# PIC32CM6408PL10028 device description
Architecture: CORTEX-M0PLUS; Family: PIC32CMPL; Series: PIC32CMPL10
Registers are 32-bit, read-write, reset 0x0 unless marked. A register's access mark holds for its fields unless they carry their own. Offsets are from the block's base; [hi:lo] are bit positions; {n}, {i} and the like mark numbered series; 'fields as' and 'values as' point back to an identical list.

## FUSES_BOOTCFG — Non-Volatile Fuses
Instances: FUSES_BOOTCFG 0x0D000400
0x00 SEQNUM reset 0xFFFFFFFF — Sequence Number Fuse
  [31:0] SEQNUM — Sequence Number
0x08 BOOTPROT reset 0xFFFFFFFF — Boot Protection Fuse
  [2:0] BOOTPROT — Boot Protection
    0=SIZE_32768BYTES (32768 bytes are protected.); 1=SIZE_16384BYTES (16384 bytes are protected.); 2=SIZE_8192BYTES (8192 bytes are protected.); 3=SIZE_4096BYTES (4096 bytes are protected.); 4=SIZE_2048BYTES (2048 bytes are protected.); 5=SIZE_1024BYTES (1024 bytes are protected.); 6=SIZE_512BYTES (512 bytes are protected.); 7=SIZE_0BYTES (0 bytes are protected.)
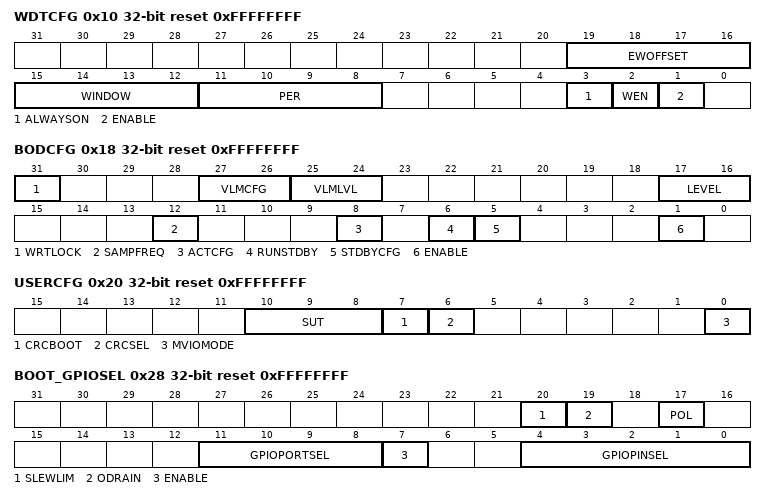
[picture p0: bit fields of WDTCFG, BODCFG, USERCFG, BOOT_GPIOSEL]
0x10 WDTCFG reset 0xFFFFFFFF — Watchdog Timer Configuration Fuse
  [19:16] EWOFFSET — Early Warning Interrupt Time Offset Fuse
    0=CYC8 (8 clock cycles); 1=CYC16 (16 clock cycles); 2=CYC32 (32 clock cycles); 3=CYC64 (64 clock cycles); 4=CYC128 (128 clock cycles); 5=CYC256 (256 clock cycles); 6=CYC512 (512 clock cycles); 7=CYC1024 (1024 clock cycles); 8=CYC2048 (2048 clock cycles); 9=CYC4096 (4096 clock cycles); 10=CYC8192 (8192 clock cycles); 11=CYC16384 (16384 clock cycles)
  [15:12] WINDOW
    values as EWOFFSET
  [11:8] PER — Time-Out Period
    values as EWOFFSET
  [3] ALWAYSON
  [2] WEN — Window Mode Enable
  [1] ENABLE
0x18 BODCFG reset 0xFFFFFFFF — BOD Configuration Fuse
  [31] WRTLOCK — Write Lock
  [27:26] VLMCFG — Voltage Level Monitor Interrupt Configuration
    0=FALLING (VDD falls below VLM threshold); 1=RISING (VDD rises above VLM threshold); 2=BOTH (VDD crosses VLM threshold)
  [25:24] VLMLVL — Voltage Level Monitor Level
    0=OFF (VLM disabled); 1=5ABOVE (VLM threshold is 5% above BOD threshold)
  [17:16] LEVEL — BOD Level
    0=BODLEVEL0 (1.90V); 1=BODLEVEL1 (2.45V); 2=BODLEVEL2 (2.70V); 3=BODLEVEL3 (2.85V)
  [12] SAMPFREQ — BOD Sampling Frequency
    0=128HZ (128 Hz Sampling Frequency); 1=32HZ (32 Hz Sampling Frequency)
  [8] ACTCFG — BOD Operation Mode in Active Mode
    0=CONT (Continuous Mode); 1=SAMP (Sampling Mode)
  [6] RUNSTDBY — Run in Standby
  [5] STDBYCFG — BOD Configuration in Standby Sleep Mode
  [1] ENABLE — BOD Enable
0x20 USERCFG reset 0xFFFFFFFF — User Configuration Fuse
  [10:8] SUT — Start-up Time
    0=0MS; 1=1MS; 2=2MS; 3=4MS; 4=8MS; 5=16MS; 6=32MS; 7=64MS
  [7] CRCBOOT
  [6] CRCSEL — CRC Polynomial Selection
    0=CRC16 (CRC-16-CCITT); 1=CRC32 (CRC-32 (IEEE 802.3))
  [0] MVIOMODE — MVIO Operation Mode
    0=DUAL (MVIO operating in dual supply mode); 1=SINGLE (MVIO operating in Single supply mode)
0x28 BOOT_GPIOSEL reset 0xFFFFFFFF — Boot External Notification I/O Pin Fuse
  [20] SLEWLIM — Slew Rate Control for Boot External Notification Signal
    0=FALSE (The slew rate is not limited (fast rise/fall time operation)); 1=TRUE (The slew rate is limited.)
  [19] ODRAIN — Open Drain Control for Boot External Notification Signal
    0=FALSE (The selected fault source is open drain drive); 1=TRUE (The selected fault source is normal drive)
  [17] POL — Select Polarity in Normal Drive Mode for Boot External Notification Signal
    0=FALSE (The selected fault source is active-high); 1=TRUE (The selected fault source is active-low)
  [11:8] GPIOPORTSEL — GPIO Port Select for Boot External Notification Signal
    0=PORTA; 1=PORTB; 2=PORTC; 3=PORTD
  [7] ENABLE — Enable Boot External Notification Signal
  [4:0] GPIOPINSEL — GPIO Pin Select for Boot External Notification Signal
    0=PIN00; 1=PIN01 (Pin 1); 30=PIN30; 31=PIN31

## FUSES_SIGNATURE — Non-Volatile Fuses
Instances: FUSES_SIGNATURE 0x0D000200
{0x20+8i} SERNUM{i} ro reset 0xFFFFFFFF (i=0..3) — Serial Number {i}

## GCLK — Generic Clock Controller
Instances: GCLK 0x40001C00
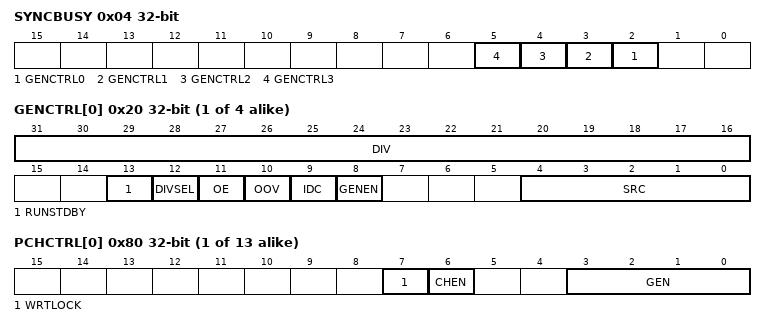
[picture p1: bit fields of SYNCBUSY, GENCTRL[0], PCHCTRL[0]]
0x04 SYNCBUSY ro — Synchronization Busy
  [n+2] GENCTRL{n} (n=0..3) — Generator Control {n} Synchronization Busy
{0x20+4i} GENCTRL[{i}] (i=0..3) (WSYNC) — Generator Control
  [31:16] DIV — Division Factor
  [13] RUNSTDBY — Run in Standby
  [12] DIVSEL — Divide Selection
    0=DIV1 (The Generator clock frequency equals the clock source frequency divided by GENCTRL[n].DIV); 1=DIV2 (The Generator clock frequency equals the clock source frequency divided by 2(GENCTRL[n].DIV + 1))
  [11] OE — Output Enable
  [10] OOV — Output Off Value
  [9] IDC — Improve Duty Cycle
  [8] GENEN — Generator Enable
  [4:0] SRC — Generator Clock Source Selection
    0=OSCHF (OSCHF oscillator output); 1=GCLKIN (Generator input pad); 2=GCLKGEN1 (Generic clock generator 1 output); 3=OSC32K (OSC32K oscillator output); 4=XOSC32K (XOSC32K oscillator output)
{0x80+4i} PCHCTRL[{i}] (i=0..12) — Peripheral Channel Control #
  [7] WRTLOCK — Write Lock
  [6] CHEN — Channel Enable
  [3:0] GEN — Generator Selection
    {v}=GCLK{v} (Generic Clock Generator {v}) (v=0..3)

## Notices in the file
Copyright (c) 2025 Microchip Technology Inc.
SPDX-License-Identifier: Apache-2.0
Licensed under the Apache License, Version 2.0 (the "License");
you may not use this file except in compliance with the License.
You may obtain a copy of the License at
http://www.apache.org/licenses/LICENSE-2.0
Unless required by applicable law or agreed to in writing, software
distributed under the License is distributed on an "AS IS" BASIS,
WITHOUT WARRANTIES OR CONDITIONS OF ANY KIND, either express or implied.
See the License for the specific language governing permissions and
limitations under the License.
